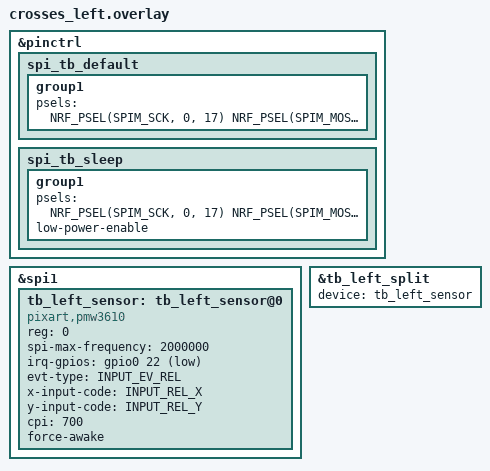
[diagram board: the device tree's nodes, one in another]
#include "crosses_trackball_shared.dtsi"
#include <zephyr/dt-bindings/input/input-event-codes.h>

/* Pin configuration */
&pinctrl {
    spi_tb_default: spi_tb_default {
        group1 {
            psels = <
                NRF_PSEL(SPIM_SCK, 0, 17)
                NRF_PSEL(SPIM_MOSI, 0, 20)
                NRF_PSEL(SPIM_MISO, 0, 6)
            >;
        };
    };

    spi_tb_sleep: spi_tb_sleep {
        group1 {
            psels = <
                NRF_PSEL(SPIM_SCK, 0, 17)
                NRF_PSEL(SPIM_MOSI, 0, 20)
                NRF_PSEL(SPIM_MISO, 0, 6)
            >;
            low-power-enable;
        };
    };
};

/* SPI configuration and trackball settings */
&spi1 {
    status = "okay";
                tb_left_sensor: tb_left_sensor@0 {
                    compatible = "pixart,pmw3610";
                    reg = <0>;
                    spi-max-frequency = <2000000>;

                    irq-gpios = <&gpio0 22 (GPIO_ACTIVE_LOW | GPIO_PULL_UP)>;

                    evt-type = <INPUT_EV_REL>;
                    x-input-code = <INPUT_REL_X>;
                    y-input-code = <INPUT_REL_Y>;

                    cpi = <700>;
                    force-awake;

                    /* Uncomment if direction adjustments are needed */
                    /* xy-swap; */
                    /* x-invert; */
                    /* y-invert; */
                };
        };

/* Peripheral: enable the split and attach it to the local physical sensor */
&tb_left_split {
    status = "okay";
    device = <&tb_left_sensor>;
};


